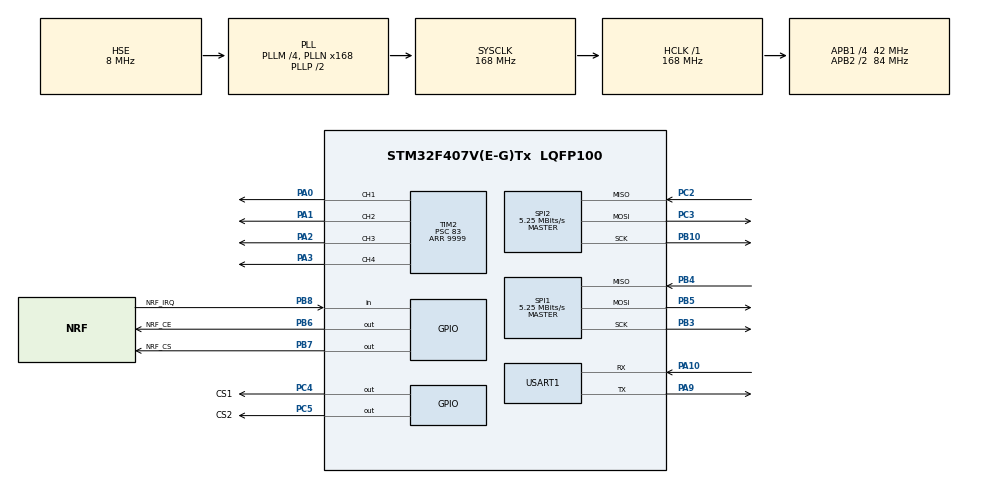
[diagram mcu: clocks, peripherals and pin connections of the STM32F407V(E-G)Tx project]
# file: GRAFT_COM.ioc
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Dma.Request0=USART1_TX
Dma.USART1_TX.0.Direction=DMA_MEMORY_TO_PERIPH
Dma.USART1_TX.0.FIFOMode=DMA_FIFOMODE_DISABLE
Dma.USART1_TX.0.Instance=DMA2_Stream7
Dma.USART1_TX.0.MemDataAlignment=DMA_MDATAALIGN_BYTE
Dma.USART1_TX.0.MemInc=DMA_MINC_ENABLE
Dma.USART1_TX.0.Mode=DMA_NORMAL
Dma.USART1_TX.0.PeriphDataAlignment=DMA_PDATAALIGN_BYTE
Dma.USART1_TX.0.PeriphInc=DMA_PINC_DISABLE
Dma.USART1_TX.0.Priority=DMA_PRIORITY_MEDIUM
Mcu.Family=STM32F4
Mcu.Name=STM32F407V(E-G)Tx
Mcu.Package=LQFP100
NVIC.DMA2_Stream7_IRQn=true\:0\:0\:false\:false\:true\:false\:true\:true
NVIC.PriorityGroup=NVIC_PRIORITYGROUP_4
NVIC.TIM3_IRQn=true\:1\:0\:true\:false\:true\:true\:true\:true
PA0-WKUP.Signal=S_TIM2_CH1_ETR
PA1.Signal=S_TIM2_CH2
PA10.Mode=Asynchronous
PA10.Signal=USART1_RX
PA13.Mode=Serial_Wire
PA13.Signal=SYS_JTMS-SWDIO
PA14.Mode=Serial_Wire
PA14.Signal=SYS_JTCK-SWCLK
PA2.Signal=S_TIM2_CH3
PA3.Signal=S_TIM2_CH4
PA9.Mode=Asynchronous
PA9.Signal=USART1_TX
PB10.Mode=Full_Duplex_Master
PB10.Signal=SPI2_SCK
PB3.Mode=Full_Duplex_Master
PB3.Signal=SPI1_SCK
PB4.Mode=Full_Duplex_Master
PB4.Signal=SPI1_MISO
PB5.Mode=Full_Duplex_Master
PB5.Signal=SPI1_MOSI
PB6.GPIO_Label=NRF_CE
PB6.GPIO_Speed=GPIO_SPEED_FREQ_HIGH
PB6.PinState=GPIO_PIN_SET
PB6.Signal=GPIO_Output
PB7.GPIO_Label=NRF_CS
PB7.GPIO_Speed=GPIO_SPEED_FREQ_HIGH
PB7.PinState=GPIO_PIN_SET
PB7.Signal=GPIO_Output
PB8.GPIO_Label=NRF_IRQ
PB8.GPIO_PuPd=GPIO_PULLUP
PB8.Signal=GPIO_Input
PC2.Mode=Full_Duplex_Master
PC2.Signal=SPI2_MISO
PC3.Mode=Full_Duplex_Master
PC3.Signal=SPI2_MOSI
PC4.GPIO_Label=CS1
PC4.GPIO_PuPd=GPIO_NOPULL
PC4.GPIO_Speed=GPIO_SPEED_FREQ_VERY_HIGH
PC4.PinState=GPIO_PIN_RESET
PC4.Signal=GPIO_Output
PC5.GPIO_Label=CS2
PC5.GPIO_ModeDefaultOutputPP=GPIO_MODE_OUTPUT_PP
PC5.GPIO_PuPd=GPIO_NOPULL
PC5.GPIO_Speed=GPIO_SPEED_FREQ_VERY_HIGH
PC5.PinState=GPIO_PIN_RESET
PC5.Signal=GPIO_Output
PH0-OSC_IN.Mode=HSE-External-Oscillator
PH0-OSC_IN.Signal=RCC_OSC_IN
PH1-OSC_OUT.Mode=HSE-External-Oscillator
PH1-OSC_OUT.Signal=RCC_OSC_OUT
ProjectManager.HeapSize=0x200
ProjectManager.StackSize=0x400
ProjectManager.TargetToolchain=MDK-ARM V5.32
RCC.48MHZClocksFreq_Value=84000000
RCC.AHBFreq_Value=168000000
RCC.APB1CLKDivider=RCC_HCLK_DIV4
RCC.APB1Freq_Value=42000000
RCC.APB1TimFreq_Value=84000000
RCC.APB2CLKDivider=RCC_HCLK_DIV2
RCC.APB2Freq_Value=84000000
RCC.APB2TimFreq_Value=168000000
RCC.CortexFreq_Value=168000000
RCC.HCLKFreq_Value=168000000
RCC.HSE_VALUE=8000000
RCC.HSI_VALUE=16000000
RCC.LSE_VALUE=32768
RCC.PLLM=4
RCC.PLLN=168
RCC.PLLSourceVirtual=RCC_PLLSOURCE_HSE
RCC.SYSCLKFreq_VALUE=168000000
RCC.SYSCLKSource=RCC_SYSCLKSOURCE_PLLCLK
RCC.VCOOutputFreq_Value=336000000
SH.S_TIM2_CH1_ETR.0=TIM2_CH1,PWM Generation1 CH1
SH.S_TIM2_CH2.0=TIM2_CH2,PWM Generation2 CH2
SH.S_TIM2_CH3.0=TIM2_CH3,PWM Generation3 CH3
SH.S_TIM2_CH4.0=TIM2_CH4,PWM Generation4 CH4
SPI1.BaudRatePrescaler=SPI_BAUDRATEPRESCALER_16
SPI1.CalculateBaudRate=5.25 MBits/s
SPI1.Direction=SPI_DIRECTION_2LINES
SPI1.Mode=SPI_MODE_MASTER
SPI1.VirtualType=VM_MASTER
SPI2.BaudRatePrescaler=SPI_BAUDRATEPRESCALER_8
SPI2.CalculateBaudRate=5.25 MBits/s
SPI2.Direction=SPI_DIRECTION_2LINES
SPI2.Mode=SPI_MODE_MASTER
SPI2.VirtualType=VM_MASTER
TIM2.AutoReloadPreload=TIM_AUTORELOAD_PRELOAD_ENABLE
TIM2.Channel-PWM\ Generation1\ CH1=TIM_CHANNEL_1
TIM2.Channel-PWM\ Generation2\ CH2=TIM_CHANNEL_2
TIM2.Channel-PWM\ Generation3\ CH3=TIM_CHANNEL_3
TIM2.Channel-PWM\ Generation4\ CH4=TIM_CHANNEL_4
TIM2.Period=9999
TIM2.Prescaler=83
TIM3.AutoReloadPreload=TIM_AUTORELOAD_PRELOAD_ENABLE
TIM3.Period=4999
TIM3.Prescaler=167
USART1.VirtualMode=VM_ASYNC
VP_TIM2_VS_ClockSourceINT.Mode=Internal
VP_TIM3_VS_ClockSourceINT.Mode=Internal
board=custom

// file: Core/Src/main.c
/* USER CODE BEGIN Header */
/**
  ******************************************************************************
  * @file           : main.c
  * @brief          : Main program body
  ******************************************************************************
  * @attention
  *
  * Copyright (c) 2023 STMicroelectronics.
  * All rights reserved.
  *
  * This software is licensed under terms that can be found in the LICENSE file
  * in the root directory of this software component.
  * If no LICENSE file comes with this software, it is provided AS-IS.
  *
  ******************************************************************************
  */
/* USER CODE END Header */
#include "main.h"
#include "dma.h"
#include "spi.h"
#include "tim.h"
#include "usart.h"
#include "gpio.h"

void SystemClock_Config(void);

int main(void)
{
  /* USER CODE BEGIN 1 */
	setvbuf(stdin,NULL,_IONBF,0);		//配置输入缓存0
  setvbuf(stdout,NULL,_IONBF,0);		//配置接收缓存0
  /* USER CODE END 1 */

  /* MCU Configuration--------------------------------------------------------*/

  /* Reset of all peripherals, Initializes the Flash interface and the Systick. */
  HAL_Init();

  /* Configure the system clock */
  SystemClock_Config();

  /* Initialize all configured peripherals */
  MX_GPIO_Init();
  MX_DMA_Init();
  MX_SPI1_Init();
  MX_USART1_UART_Init();
  MX_SPI2_Init();
  MX_TIM2_Init();
  MX_TIM3_Init();
  /* USER CODE BEGIN 2 */
  ALL_Init();

  /* USER CODE END 2 */

  /* Infinite loop */
  /* USER CODE BEGIN WHILE */
  while (1)
  {

    example_anto_send();
    //printf("GX=%5f   GY=%5f   GZ=%5f\N",BMI088_GYRO_F.x,BMI088_GYRO_F.y,BMI088_GYRO_F.z);
    //printf("AX=%5f AY=%5f AZ=%5f",BMI088_ACC_F.x,BMI088_ACC_F.y,BMI088_ACC_F.z);
    //printf("pitch=%4f  yaw=%4f  roll=%4f\n"         ,Angle.pitch,Angle.yaw,Angle.roll);
    //printf("pitch=%4d  yaw=%4d  roll=%4d  thr=%4d\n",Remote.pitch,Remote.yaw,Remote.roll,Remote.thr);

    //ANTO_Send(ANTO_MOTOR);
    /* USER CODE END WHILE */

  }
}

void SystemClock_Config(void)
{
  RCC_OscInitTypeDef RCC_OscInitStruct = {0};
  RCC_ClkInitTypeDef RCC_ClkInitStruct = {0};

  /** Configure the main internal regulator output voltage
  */
  __HAL_RCC_PWR_CLK_ENABLE();
  __HAL_PWR_VOLTAGESCALING_CONFIG(PWR_REGULATOR_VOLTAGE_SCALE1);

  /** Initializes the RCC Oscillators according to the specified parameters
  * in the RCC_OscInitTypeDef structure.
  */
  RCC_OscInitStruct.OscillatorType = RCC_OSCILLATORTYPE_HSE;
  RCC_OscInitStruct.HSEState = RCC_HSE_ON;
  RCC_OscInitStruct.PLL.PLLState = RCC_PLL_ON;
  RCC_OscInitStruct.PLL.PLLSource = RCC_PLLSOURCE_HSE;
  RCC_OscInitStruct.PLL.PLLM = 4;
  RCC_OscInitStruct.PLL.PLLN = 168;
  RCC_OscInitStruct.PLL.PLLP = RCC_PLLP_DIV2;
  RCC_OscInitStruct.PLL.PLLQ = 4;
  if (HAL_RCC_OscConfig(&RCC_OscInitStruct) != HAL_OK)
  {
    Error_Handler();
  }

  /** Initializes the CPU, AHB and APB buses clocks
  */
  RCC_ClkInitStruct.ClockType = RCC_CLOCKTYPE_HCLK|RCC_CLOCKTYPE_SYSCLK
                              |RCC_CLOCKTYPE_PCLK1|RCC_CLOCKTYPE_PCLK2;
  RCC_ClkInitStruct.SYSCLKSource = RCC_SYSCLKSOURCE_PLLCLK;
  RCC_ClkInitStruct.AHBCLKDivider = RCC_SYSCLK_DIV1;
  RCC_ClkInitStruct.APB1CLKDivider = RCC_HCLK_DIV4;
  RCC_ClkInitStruct.APB2CLKDivider = RCC_HCLK_DIV2;

  if (HAL_RCC_ClockConfig(&RCC_ClkInitStruct, FLASH_LATENCY_5) != HAL_OK)
  {
    Error_Handler();
  }
}

void Error_Handler(void)
{
  __disable_irq();
  while (1)
  {
  }
}
